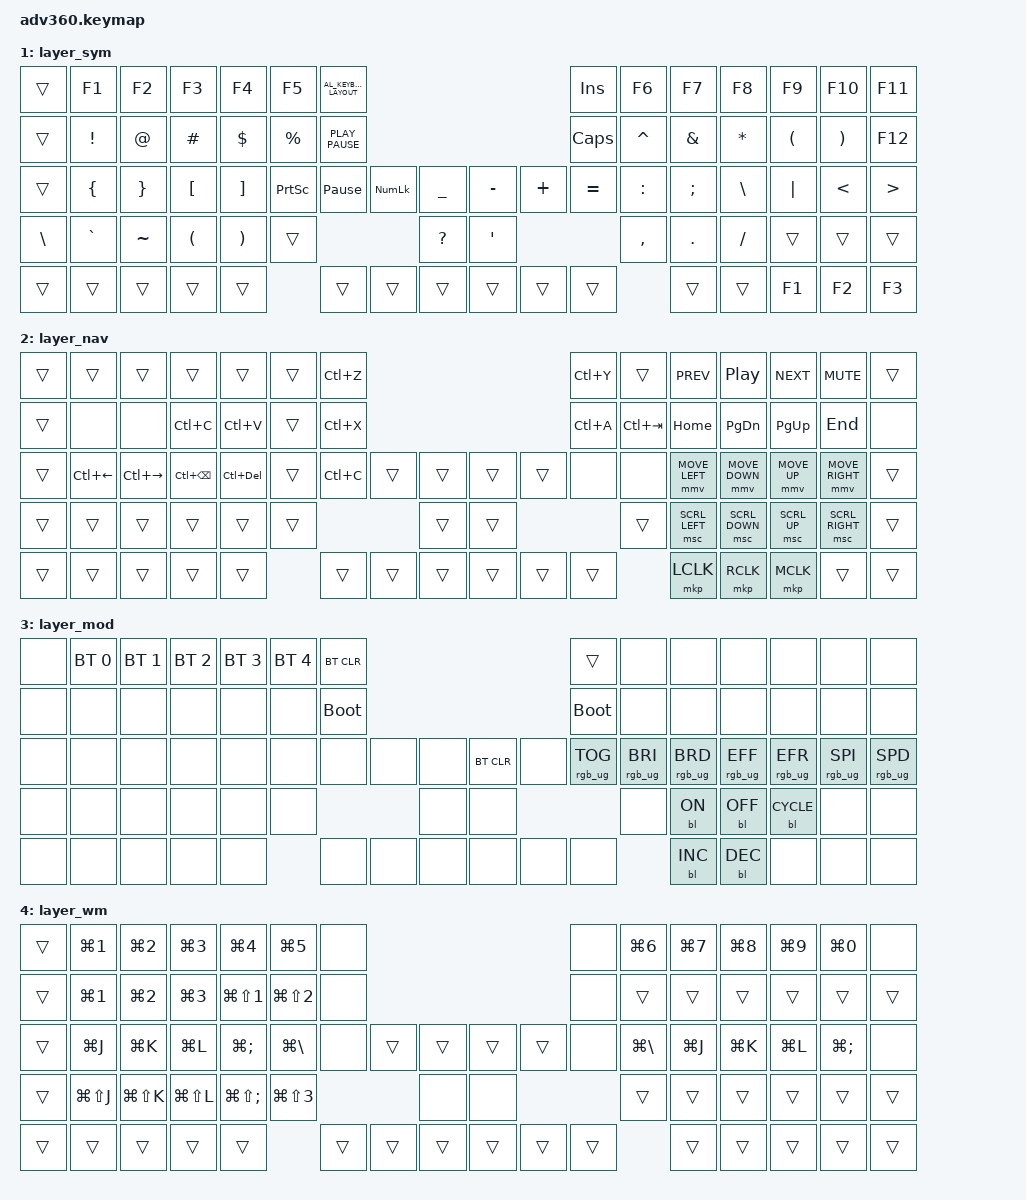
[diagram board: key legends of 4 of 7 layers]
/*
 * ZMK keymap for Kinesis Advantage360 Pro
 * Layers:
 * 0 BASE (QWERTY + HRM; thumb: tap End / hold Shift)
 * 1 SYM  (hold BSPC/DEL)
 * 2 NAV  (hold SPACE)
 * 3 MOD  (BT/RGB/boot)
 * 4 WM   (hold ENTER) -> focus with Enter+key; move requires Shift
 * 5 NUMPAD (momentary from base top row)
 * 6 APP  (hold CAPS) -> Ctrl+Alt+Win+<key> for quicklaunch/system binds
 */

#include <behaviors.dtsi>
#include <dt-bindings/zmk/backlight.h>
#include <dt-bindings/zmk/bt.h>
#include <dt-bindings/zmk/keys.h>
#include <dt-bindings/zmk/rgb.h>
#include <dt-bindings/zmk/mouse.h>

/ {
    behaviors {
        hm: home_row_mods {
            compatible = "zmk,behavior-hold-tap";
            label = "HOME_ROW_MODS";
            #binding-cells = <2>;
            tapping-term-ms = <200>;
            quick-tap-ms = <0>;
            require-prior-idle-ms = <150>;
            flavor = "tap-preferred";
            bindings = <&kp>, <&kp>;
        };
        cw: caps_word {
            compatible = "zmk,behavior-caps-word";
            label = "CAPS_WORD";
            #binding-cells = <0>;
            continue-list = <UNDERSCORE MINUS BACKSPACE DELETE>;
        };
    };

    combos {
        compatible = "zmk,combos";
        combo_esc {
            timeout-ms = <50>;
            key-positions = <31 32>;
            bindings = <&kp ESC>;
        };
        combo_bspc {
            timeout-ms = <50>;
            key-positions = <33 34>;
            bindings = <&kp BSPC>;
        };
        combo_enter {
            timeout-ms = <50>;
            key-positions = <43 44>;
            bindings = <&kp ENTER>;
        };
        combo_del {
            timeout-ms = <50>;
            key-positions = <41 42>;
            bindings = <&kp DEL>;
        };
    };

    keymap {
        compatible = "zmk,keymap";

        // =========================================================
        // LAYER 0: BASE
        // =========================================================

        default_layer {
            bindings = <
&kp EQUAL  &kp N1                &kp N2                 &kp N3       &kp N4       &kp N5  &mo 5                                                                            &mo 3               &kp N6  &kp N7       &kp N8       &kp N9      &kp N0         &kp MINUS
&kp TAB    &kp Q                 &kp W                  &kp E        &kp R        &kp T   &kp PRINTSCREEN                                                                  &kp K_CONTEXT_MENU  &kp Y   &kp U        &kp I        &kp O       &kp P          &kp BSLH
&kp ESC    &hm LGUI A            &hm LALT S             &hm LCTRL D  &hm LSHFT F  &kp G   &kp LC(PRINTSCREEN)  &kp LCTRL  &kp LEFT_ALT       &kp RCTRL  &kp RIGHT_COMMAND  &mt LC(V) LC(C)     &kp H   &hm RSHFT J  &hm RCTRL K  &hm RALT L  &hm RGUI SEMI  &kp SQT
&kp LSHFT  &kp Z                 &kp X                  &kp C        &kp V        &kp B                                   &lt 6 &cw          &kp PG_UP                                         &kp N   &kp M        &kp COMMA    &kp DOT     &kp FSLH       &kp RSHFT
&kp GRAVE  &kp LEFT_PARENTHESIS  &kp RIGHT_PARENTHESIS  &kp LEFT     &kp RIGHT            &lt 1 BSPC           &lt 5 DEL  &mt LSHFT END      &kp K_APP  &lt 4 ENTER        &lt 2 SPACE                 &kp UP       &kp DOWN     &kp LBKT    &kp RBKT       &mo 2
            >;
        };

        // =========================================================
        // LAYER 1: SYM
        // =========================================================

        layer_sym {
            bindings = <
&trans    &kp F1     &kp F2     &kp F3                &kp F4                 &kp F5           &kp C_AL_KEYBOARD_LAYOUT                                                  &kp INS    &kp F6     &kp F7    &kp F8         &kp F9    &kp F10   &kp F11
&trans    &kp EXCL   &kp AT     &kp HASH              &kp DLLR               &kp PRCNT        &kp K_PLAY_PAUSE                                                          &kp CAPS   &kp CARET  &kp AMPS  &kp STAR       &kp LPAR  &kp RPAR  &kp F12
&trans    &kp LBRC   &kp RBRC   &kp LBKT              &kp RBKT               &kp PRINTSCREEN  &kp PAUSE_BREAK           &kp KP_NUM  &kp UNDER      &kp MINUS  &kp PLUS  &kp EQUAL  &kp COLON  &kp SEMI  &kp BACKSLASH  &kp PIPE  &kp LT    &kp GT
&kp BSLH  &kp GRAVE  &kp TILDE  &kp LEFT_PARENTHESIS  &kp RIGHT_PARENTHESIS  &trans                                                 &kp QMARK      &kp SQT                         &kp COMMA  &kp DOT   &kp FSLH       &trans    &trans    &trans
&trans    &trans     &trans     &trans                &trans                                  &trans                    &trans      &trans         &trans     &trans    &trans                &trans    &trans         &kp F1    &kp F2    &kp F3
            >;
        };

        // =========================================================
        // LAYER 2: NAV
        // =========================================================

        layer_nav {
            bindings = <
&trans  &trans        &trans         &trans        &trans       &trans  &kp LC(Z)                                      &kp LC(Y)  &trans       &kp C_PREV  &kp C_PP        &kp C_NEXT    &kp C_MUTE  &trans
&trans  &none         &none          &kp LC(C)     &kp LC(V)    &trans  &kp LC(X)                                      &kp LC(A)  &kp LC(TAB)  &kp HOME    &kp PAGE_DOWN   &kp PG_UP     &kp END     &none
&trans  &kp LC(LEFT)  &kp LC(RIGHT)  &kp LC(BSPC)  &kp LC(DEL)  &trans  &kp LC(C)  &trans  &trans      &trans  &trans  &none      &none        &mmv MOVE_LEFT &mmv MOVE_DOWN &mmv MOVE_UP &mmv MOVE_RIGHT &trans
&trans  &trans        &trans         &trans        &trans       &trans                     &trans      &trans                     &trans       &msc SCRL_LEFT &msc SCRL_DOWN &msc SCRL_UP &msc SCRL_RIGHT &trans
&trans  &trans        &trans         &trans        &trans               &trans     &trans  &trans      &trans  &trans  &trans                  &mkp LCLK   &mkp RCLK       &mkp MCLK     &trans      &trans
            >;
        };

        // =========================================================
        // LAYER 3: MOD (BT/RGB/boot)
        // =========================================================

        layer_mod {
            bindings = <
&none  &bt BT_SEL 0  &bt BT_SEL 1  &bt BT_SEL 2  &bt BT_SEL 3  &bt BT_SEL 4  &bt BT_CLR                                        &trans           &none            &none            &none            &none            &none            &none
&none  &none         &none         &none         &none         &none         &bootloader                                       &bootloader      &none            &none            &none            &none            &none            &none
&none  &none         &none         &none         &none         &none         &none        &none  &none      &bt BT_CLR  &none  &rgb_ug RGB_TOG  &rgb_ug RGB_BRI  &rgb_ug RGB_BRD  &rgb_ug RGB_EFF  &rgb_ug RGB_EFR  &rgb_ug RGB_SPI  &rgb_ug RGB_SPD
&none  &none         &none         &none         &none         &none                             &none      &none                               &none            &bl BL_ON        &bl BL_OFF       &bl BL_CYCLE     &none            &none
&none  &none         &none         &none         &none                       &none        &none  &none      &none       &none  &none                             &bl BL_INC       &bl BL_DEC       &none            &none            &none
            >;
        };

        // =========================================================
        // LAYER 4: WM
        // =========================================================

        layer_wm {
            bindings = <
&trans  &kp LG(N1)     &kp LG(N2)     &kp LG(N3)         &kp LG(N4)         &kp LG(N5)     &none                                                                            &none      &kp LG(N6)  &kp LG(N7)   &kp LG(N8)   &kp LG(N9)   &kp LG(N0)       &none
&trans  &kp LG(N1)     &kp LG(N2)     &kp LG(N3)         &kp LG(LS(N1))     &kp LG(LS(N2)) &none                                                                            &none      &trans      &trans       &trans       &trans       &trans           &trans
&trans  &kp LG(J)      &kp LG(K)      &kp LG(L)          &kp LG(SEMI)       &kp LG(BSLH)   &none                &trans  &trans      &trans  &trans  &none      &kp LG(BSLH) &kp LG(J)   &kp LG(K)    &kp LG(L)    &kp LG(SEMI)     &none
&trans  &kp LG(LS(J))  &kp LG(LS(K))  &kp LG(LS(L))      &kp LG(LS(SEMI))   &kp LG(LS(N3))                               &none       &none                      &trans       &trans      &trans       &trans       &trans           &trans
&trans  &trans         &trans         &trans             &trans                            &trans               &trans  &trans      &trans  &trans  &trans                  &trans      &trans       &trans       &trans           &trans
            >;
        };

        // =========================================================
        // LAYER 5: NUMPAD
        // =========================================================

        layer_numpad {
            bindings = <
&trans  &trans    &trans  &trans     &trans    &trans       &trans                                                                 &trans  &trans           &kp MINUS     &kp PLUS      &kp EQUAL     &kp PIPE       &trans
&trans  &trans    &trans  &trans     &trans    &trans       &kp KP_SLASH                                                           &trans  &trans           &kp N7        &kp N8        &kp N9        &kp BACKSLASH  &trans
&trans  &kp EXCL  &kp AT  &kp POUND  &kp DLLR  &kp PERCENT  &kp KP_MULTIPLY  &trans  &trans            &trans       &trans         &trans  &kp LOCKING_NUM  &kp NUMBER_4  &kp N5        &kp NUMBER_6  &kp DOT        &trans
&trans  &trans    &trans  &trans     &trans    &trans                                &kp KP_MINUS      &kp KP_PLUS                         &kp N0           &kp NUMBER_1  &kp NUMBER_2  &kp NUMBER_3  &kp SLASH      &trans
&trans  &trans    &trans  &trans     &trans                 &trans           &trans  &trans            &trans       &kp BACKSPACE  &trans                   &kp N0        &trans        &trans        &trans
            >;
        };

        // =========================================================
        // LAYER 6: APP (USE ALL KEYS)
        // Hold CAPS to access.
        // Sends Ctrl+Alt+Win+<key> for every position (except CAPS itself which is held).
        // Bind these in GlazeWM to launch apps / scripts.
        // =========================================================

        layer_app {
            bindings = <
&kp LC(LA(LG(EQUAL)))  &kp LC(LA(LG(N1)))     &kp LC(LA(LG(N2)))  &kp LC(LA(LG(N3)))    &kp LC(LA(LG(N4)))     &kp LC(LA(LG(N5)))  &kp LC(LA(LG(F1)))                                                                                                 &kp LC(LA(LG(F2)))     &kp LC(LA(LG(N6)))  &kp LC(LA(LG(N7)))  &kp LC(LA(LG(N8)))     &kp LC(LA(LG(N9)))    &kp LC(LA(LG(N0)))    &kp LC(LA(LG(MINUS)))
&kp LC(LA(LG(TAB)))    &kp LC(LA(LG(Q)))      &kp LC(LA(LG(W)))   &kp LC(LA(LG(E)))     &kp LC(LA(LG(R)))      &kp LC(LA(LG(T)))   &kp LC(LA(LG(F3)))                                                                                                 &kp LC(LA(LG(F4)))     &kp LC(LA(LG(Y)))   &kp LC(LA(LG(U)))   &kp LC(LA(LG(I)))      &kp LC(LA(LG(O)))     &kp LC(LA(LG(P)))     &kp LC(LA(LG(BSLH)))
&kp LC(LA(LG(ESC)))    &kp LC(LA(LG(A)))      &kp LC(LA(LG(S)))   &kp LC(LA(LG(D)))     &kp LC(LA(LG(F)))      &kp LC(LA(LG(G)))   &kp LC(LA(LG(F5)))    &kp LC(LA(LG(F6)))   &kp LC(LA(LG(F7)))        &kp LC(LA(LG(F8)))     &kp LC(LA(LG(F9)))     &kp LC(LA(LG(F10)))    &kp LC(LA(LG(H)))   &kp LC(LA(LG(J)))   &kp LC(LA(LG(K)))      &kp LC(LA(LG(L)))     &kp LC(LA(LG(SEMI)))  &kp LC(LA(LG(SQT)))
&kp LC(LA(LG(LSHFT)))  &kp LC(LA(LG(Z)))      &kp LC(LA(LG(X)))   &kp LC(LA(LG(C)))     &kp LC(LA(LG(V)))      &kp LC(LA(LG(B)))                                              &kp LC(LA(LG(HOME)))      &kp LC(LA(LG(PG_UP)))                                                &kp LC(LA(LG(N)))   &kp LC(LA(LG(M)))   &kp LC(LA(LG(COMMA)))  &kp LC(LA(LG(DOT)))   &kp LC(LA(LG(FSLH)))  &kp LC(LA(LG(RSHFT)))
&kp LC(LA(LG(GRAVE)))  &kp LC(LA(LG(GRAVE)))  &trans              &kp LC(LA(LG(LEFT)))  &kp LC(LA(LG(RIGHT)))                      &kp LC(LA(LG(BSPC)))  &kp LC(LA(LG(DEL)))  &kp LC(LA(LG(END)))       &kp LC(LA(LG(PG_DN)))  &kp LC(LA(LG(ENTER)))  &kp LC(LA(LG(SPACE)))                      &kp LC(LA(LG(UP)))  &kp LC(LA(LG(DOWN)))   &kp LC(LA(LG(LBKT)))  &kp LC(LA(LG(RBKT)))  &kp LC(LA(LG(F11)))
            >;
        };
    };
};
